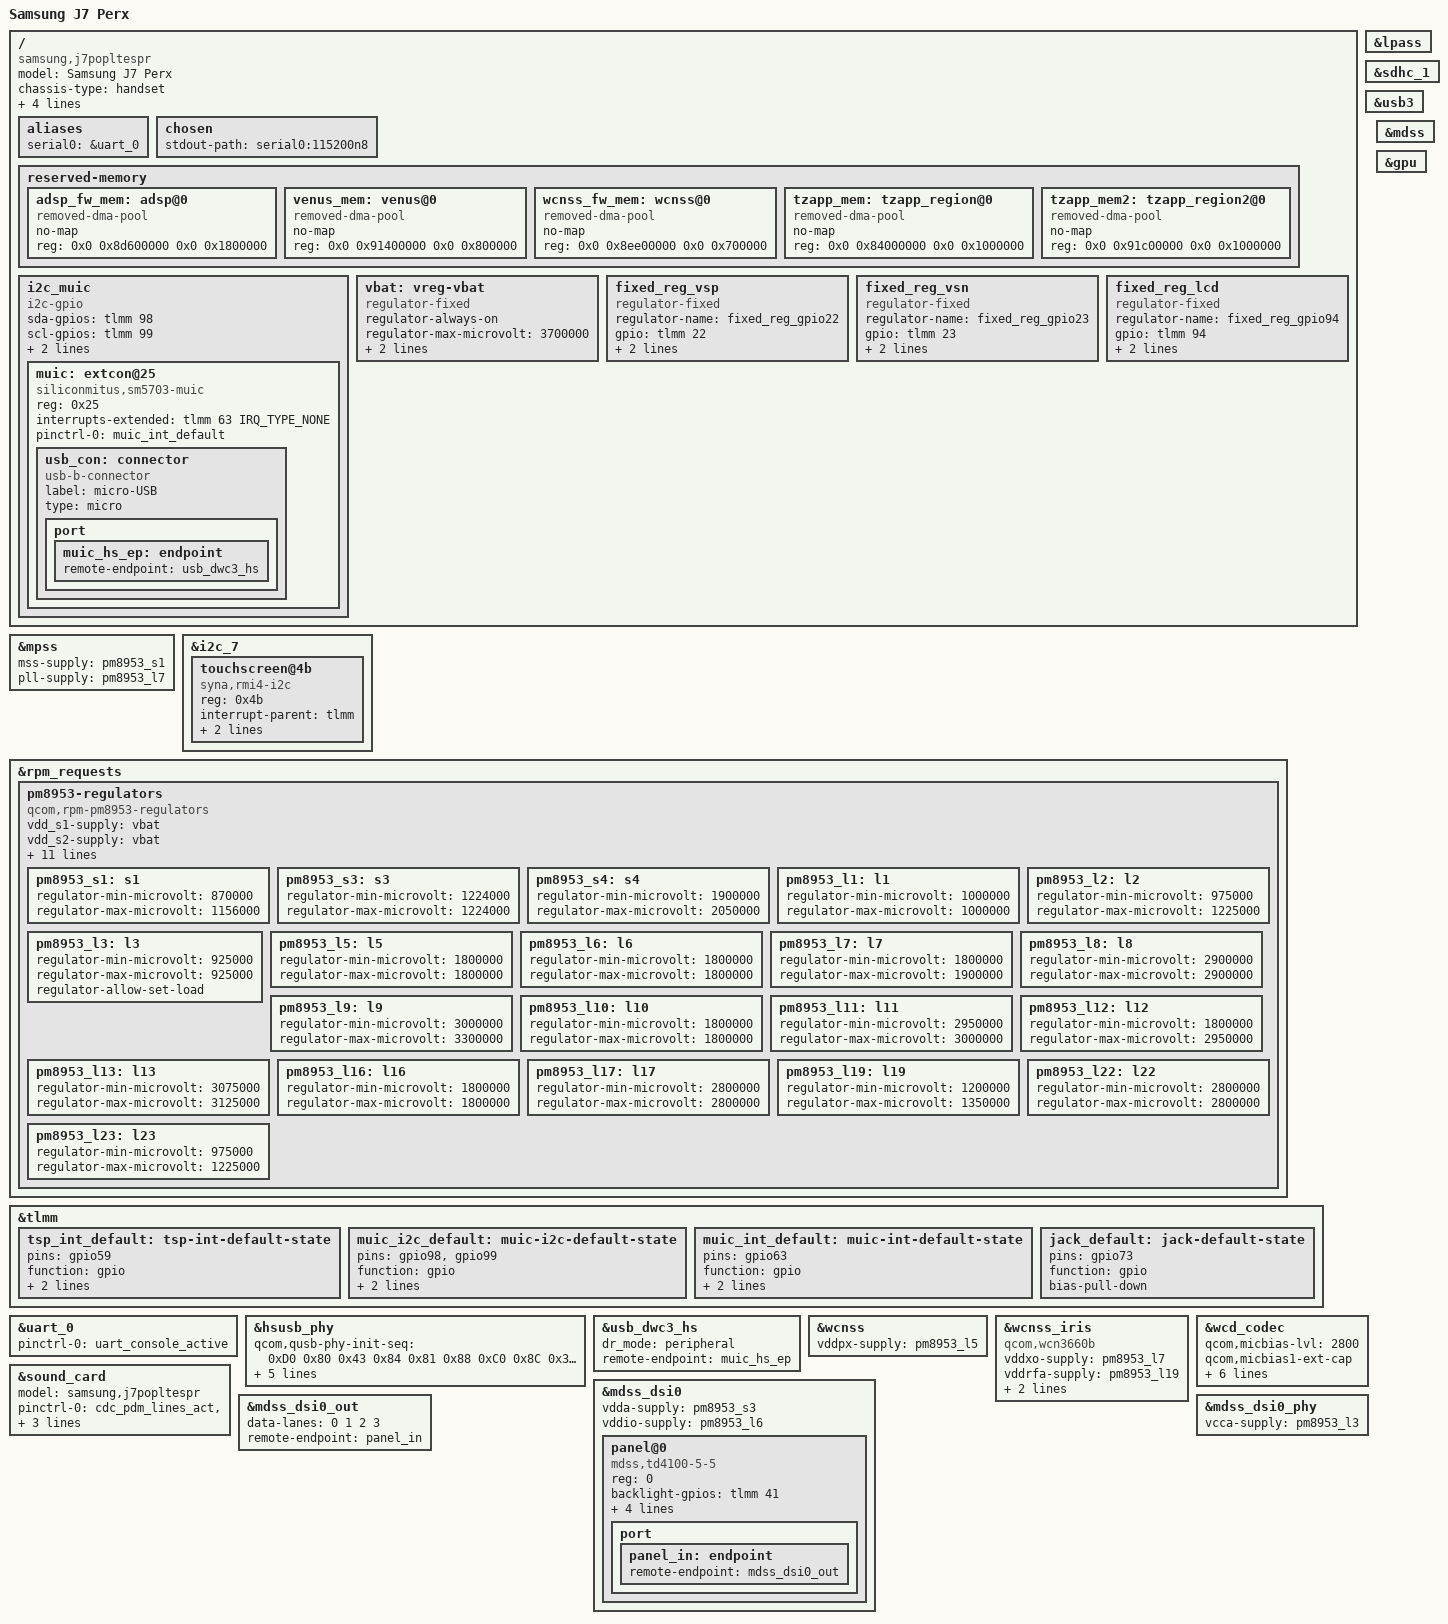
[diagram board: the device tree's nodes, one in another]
// SPDX-License-Identifier: BSD-3-Clause
/*
 * Copyright (c) 2022, Sireesh Kodali
 */
/dts-v1/;

#include "msm8953.dtsi"
#include <dt-bindings/arm/qcom,ids.h>
#include "pm8953.dtsi"
#include "pmi8950.dtsi"

/delete-node/ &cont_splash_mem;
/delete-node/ &qseecom_mem;

/ {
	model = "Samsung J7 Perx";
	compatible = "samsung,j7popltespr", "qcom,msm8953";
	chassis-type = "handset";
	qcom,msm-id = <QCOM_ID_MSM8953 0>;
	qcom,board-id = <QCOM_BOARD_ID_MTP 1>,
			<QCOM_BOARD_ID_MTP 2>,
			<QCOM_BOARD_ID_MTP 3>,
			<QCOM_BOARD_ID_MTP 4>,
			<QCOM_BOARD_ID_MTP 5>;

	aliases {
		serial0 = &uart_0;
	};


	chosen {
		#address-cells = <2>;
		#size-cells = <2>;
		ranges;
		stdout-path = "serial0:115200n8";
		/*
		framebuffer@90001000 {
			compatible = "simple-framebuffer";
			reg = <0 0x90001000 0 (1280 * 720 * 3)>;
			width = <720>;
			height = <1280>;
			stride = <(720 * 3)>;
			format = "r8g8b8";
		};
		*/
		
	};

	reserved-memory {
		/*
		framebuffer_region@90001000 {
			reg = <0x00 0x90001000 0x00 0x300000>;
			no-map;
		};
		*/
		
		/delete-node/ adsp@8d600000;
		adsp_fw_mem: adsp@0 {
			compatible = "removed-dma-pool";
			no-map;
			reg = <0x0 0x8d600000 0x0 0x1800000>;
		};
		
		/delete-node/ venus@91400000;
		venus_mem: venus@0 {
			compatible = "removed-dma-pool";
			no-map;
			reg = <0x0 0x91400000 0x0 0x800000>;
		};
		
		/delete-node/ wcnss@8e700000;
		wcnss_fw_mem: wcnss@0 {
			compatible = "removed-dma-pool";
			no-map;
			reg = <0x0 0x8ee00000 0x0 0x700000>;
		};

		/delete-node/ tzapp_region@0;
		
		tzapp_mem: tzapp_region@0 {
			compatible = "removed-dma-pool";
			no-map;
			reg = <0x0 0x84000000 0x0 0x1000000>;
		};
		/* Later board/BL revisions move tz_appregion?, either way results in a fail to boot */
		tzapp_mem2: tzapp_region2@0 {
			compatible = "removed-dma-pool";
			no-map;
			reg = <0x0 0x91c00000 0x0 0x1000000>;
		};
	};

	i2c_muic {
		compatible = "i2c-gpio";
		sda-gpios = <&tlmm 98 (GPIO_ACTIVE_HIGH|GPIO_OPEN_DRAIN)>;
		scl-gpios = <&tlmm 99 (GPIO_ACTIVE_HIGH|GPIO_OPEN_DRAIN)>;

		pinctrl-names = "default";
		pinctrl-0 = <&muic_i2c_default>;
		i2c-gpio,delay-us = <2>;

		#address-cells = <1>;
		#size-cells = <0>;

		muic: extcon@25 {
			compatible = "siliconmitus,sm5703-muic";
			reg = <0x25>;

			interrupts-extended = <&tlmm 63 IRQ_TYPE_NONE>;

			pinctrl-names = "default";
			pinctrl-0 = <&muic_int_default>;

			usb_con: connector {
				compatible = "usb-b-connector";
				label = "micro-USB";
				type = "micro";

				port {
					muic_hs_ep: endpoint {
						remote-endpoint = <&usb_dwc3_hs>;
					};

				};

			};									
		};
	};

	vbat: vreg-vbat {
		compatible = "regulator-fixed";
		regulator-always-on;
		regulator-max-microvolt = <3700000>;
		regulator-min-microvolt = <3700000>;
		regulator-name = "VBAT";
	};
	
	/* VSP 5.4V */
	fixed_reg_vsp: fixed_reg_vsp {
		 compatible = "regulator-fixed";
		 status = "okay";
		 regulator-name = "fixed_reg_gpio22";
		 gpio = <&tlmm 22 0>; // PANEL_ENP
		 enable-active-high;
		 regulator-boot-on;
	};

	/* VSN -5.4V */
	fixed_reg_vsn: fixed_reg_vsn {
		 compatible = "regulator-fixed";
		 status = "okay";
		 regulator-name = "fixed_reg_gpio23";
		 gpio = <&tlmm 23 0>; // PANEL_ENN
		 enable-active-high;
		 regulator-boot-on;
	};


	fixed_reg_lcd: fixed_reg_lcd {
		 compatible = "regulator-fixed";
		 status = "okay";
		 regulator-name = "fixed_reg_gpio94";
		 gpio = <&tlmm 94 0>;
		 enable-active-high;
		 regulator-boot-on;
	};



};

&mpss {
	mss-supply = <&pm8953_s1>;
	pll-supply = <&pm8953_l7>;

	status = "okay";
};

&i2c_7 {
	status = "okay";

	touchscreen@4b {
		reg = <0x4b>;
		compatible = "syna,rmi4-i2c";

		interrupt-parent = <&tlmm>;
		interrupts = <59 IRQ_TYPE_EDGE_FALLING>;

		pinctrl-names = "default";
		pinctrl-0 = <&tsp_int_default>;
	};
};

&lpass {
	status = "okay";
};

&rpm_requests {
	pm8953-regulators {
		compatible = "qcom,rpm-pm8953-regulators";
		vdd_s1-supply = <&vbat>;
		vdd_s2-supply = <&vbat>;
		vdd_s3-supply = <&vbat>;
		vdd_s4-supply = <&vbat>;
		vdd_s5-supply = <&vbat>;
		vdd_s6-supply = <&vbat>;
		vdd_s7-supply = <&vbat>;
		vdd_l1-supply = <&pm8953_s3>;
		vdd_l2_l3-supply = <&pm8953_s3>;
		vdd_l4_l5_l6_l7_l16_l19-supply = <&pm8953_s4>;
		vdd_l8_l11_l12_l13_l14_l15-supply = <&vbat>;
		vdd_l9_l10_l17_l18_l22-supply = <&vbat>;
		vdd_l23-supply = <&pm8953_s3>;

		pm8953_s1: s1 {
			regulator-min-microvolt = <870000>;
			regulator-max-microvolt = <1156000>;
		};


		pm8953_s3: s3 {
			regulator-min-microvolt = <1224000>;
			regulator-max-microvolt = <1224000>;
		};

		pm8953_s4: s4 {
			regulator-min-microvolt = <1900000>;
			regulator-max-microvolt = <2050000>;
		};

		pm8953_l1: l1 {
			regulator-min-microvolt = <1000000>;
			regulator-max-microvolt = <1000000>;
		};

		pm8953_l2: l2 {
			regulator-min-microvolt = <975000>;
			regulator-max-microvolt = <1225000>;
		};

		pm8953_l3: l3 {
			regulator-min-microvolt = <925000>;
			regulator-max-microvolt = <925000>;
			regulator-allow-set-load;
		};

		pm8953_l5: l5 {
			regulator-min-microvolt = <1800000>;
			regulator-max-microvolt = <1800000>;
		};

		pm8953_l6: l6 {
			regulator-min-microvolt = <1800000>;
			regulator-max-microvolt = <1800000>;
		};

		pm8953_l7: l7 {
			regulator-min-microvolt = <1800000>;
			regulator-max-microvolt = <1900000>;
		};

		pm8953_l8: l8 {
			regulator-min-microvolt = <2900000>;
			regulator-max-microvolt = <2900000>;
		};

		pm8953_l9: l9 {
			regulator-min-microvolt = <3000000>;
			regulator-max-microvolt = <3300000>;
		};

		pm8953_l10: l10 {
			regulator-min-microvolt = <1800000>;
			regulator-max-microvolt = <1800000>;
		};

		pm8953_l11: l11 {
			regulator-min-microvolt = <2950000>;
			regulator-max-microvolt = <3000000>;
		};

		pm8953_l12: l12 {
			regulator-min-microvolt = <1800000>;
			regulator-max-microvolt = <2950000>;
		};

		pm8953_l13: l13 {
			regulator-min-microvolt = <3075000>;
			regulator-max-microvolt = <3125000>;
		};

		pm8953_l16: l16 {
			regulator-min-microvolt = <1800000>;
			regulator-max-microvolt = <1800000>;
		};

		pm8953_l17: l17 {
			regulator-min-microvolt = <2800000>;
			regulator-max-microvolt = <2800000>;
		};

		pm8953_l19: l19 {
			regulator-min-microvolt = <1200000>;
			regulator-max-microvolt = <1350000>;
		};

		pm8953_l22: l22 {
			regulator-min-microvolt = <2800000>;
			regulator-max-microvolt = <2800000>;
		};

		pm8953_l23: l23 {
			regulator-min-microvolt = <975000>;
			regulator-max-microvolt = <1225000>;
		};
	};
};



&tlmm {
	tsp_int_default: tsp-int-default-state {
		pins = "gpio59";
		function = "gpio";
		
		drive-strength = <2>;
		bias-disable;
	};
	muic_i2c_default: muic-i2c-default-state {
		pins = "gpio98", "gpio99";
		function = "gpio";

		drive-strength = <2>;
		bias-disable;
	};

	muic_int_default: muic-int-default-state {
		pins = "gpio63";
		function = "gpio";

		drive-strength = <2>;
		bias-disable;
	};
	jack_default: jack-default-state {
		pins = "gpio73";
		function = "gpio";
		bias-pull-down;
	};
};

&sdhc_1 {
	status = "okay";
};


&uart_0 {
        pinctrl-0 = <&uart_console_active>;
        pinctrl-names = "default";

        status = "okay"; 
};

&usb3 {
	status = "okay";
};

&hsusb_phy {
	qcom,qusb-phy-init-seq = <0xD0 0x80
				0x43 0x84
				0x81 0x88
				0xC0 0x8C
				0x30 0x08
				0x79 0x0C
				0x21 0x10
				0x14 0x9C
				0x9F 0x1C
				0x00 0x18>;
	qcom,qusb-phy-init-seq-host = <0xD0 0x80
				0xA3 0x84
				0x81 0x88
				0xC0 0x8C
				0x30 0x08
				0x79 0x0C
				0x21 0x10
				0x14 0x9C
				0x9F 0x1C
				0x00 0x18>;
	vdd-supply = <&pm8953_l3>;
	vdda-pll-supply = <&pm8953_l7>;
	vdda-phy-dpdm-supply = <&pm8953_l13>;
	status = "okay";
};

&usb_dwc3_hs {
	dr_mode = "peripheral";
	remote-endpoint = <&muic_hs_ep>;
};

&wcnss {
	vddpx-supply = <&pm8953_l5>;
	status = "okay";
};

&wcnss_iris {
	compatible = "qcom,wcn3660b";
	vddxo-supply = <&pm8953_l7>;
	vddrfa-supply = <&pm8953_l19>;
	vddpa-supply = <&pm8953_l9>;
	vdddig-supply = <&pm8953_l5>;
	status = "okay";
};

&wcd_codec {
	qcom,micbias-lvl = <2800>;
	qcom,micbias1-ext-cap;
	qcom,micbias2-ext-cap;
	qcom,mbhc-vthreshold-low = <150 225 450 500 600>;
	qcom,mbhc-vthreshold-high = <150 225 450 500 600>;
	vdd-cdc-io-supply = <&pm8953_l5>;
	vdd-cdc-tx-rx-cx-supply = <&pm8953_s4>;
	vdd-micbias-supply = <&pm8953_l13>;
	status = "okay";
};

&sound_card {
	model = "samsung,j7popltespr";
	status = "okay";
	
	pinctrl-names = "default", "sleep";
	pinctrl-0 = <&cdc_pdm_lines_act &cdc_pdm_lines_2_act &cdc_pdm_comp_lines_act>;
	pinctrl-1 = <&cdc_pdm_lines_sus &cdc_pdm_lines_2_sus &cdc_pdm_comp_lines_act>;
};

&mdss {
	status = "okay";
};
&gpu {
	status = "okay";
};
&mdss_dsi0 {
	vdda-supply = <&pm8953_s3>;
	vddio-supply = <&pm8953_l6>;
	status = "okay";
	/*
	panel@0 {
		compatible = "syna,td4101-panel";
		reg = <0>;
		
		backlight-gpios = <&tlmm 41 GPIO_ACTIVE_HIGH>;
		reset-gpios = <&tlmm 50 GPIO_ACTIVE_HIGH>;
		vio-supply = <&fixed_reg_lcd>;
		vsn-supply = <&fixed_reg_vsn>;
		vsp-supply = <&fixed_reg_vsp>;
		width-mm = <69>;
		height-mm = <122>;
		panel-timing {
			clock-frequency = <112878360>;
			hactive = <720>;
			hsync-len = <4>;
			hfront-porch = <252>;
			hback-porch = <158>;
			
			vactive = <1280>;
			vsync-len = <127>;
			vfront-porch = <127>;
			vback-porch = <125>;
		
		};
		port {
			panel_in: endpoint {
				remote-endpoint = <&mdss_dsi0_out>;
			};
		};
	};
	*/
	panel@0 {
		compatible = "mdss,td4100-5-5";
		reg = <0>;
		backlight-gpios = <&tlmm 41 GPIO_ACTIVE_HIGH>;
		reset-gpios = <&tlmm 50 GPIO_ACTIVE_HIGH>;
		vio-supply = <&fixed_reg_lcd>;
		vsn-supply = <&fixed_reg_vsn>;
		vsp-supply = <&fixed_reg_vsp>;
		port {
			panel_in: endpoint {
				remote-endpoint = <&mdss_dsi0_out>;
			};
		};
	};
};


&mdss_dsi0_out {
	data-lanes = <0 1 2 3>;
	remote-endpoint = <&panel_in>;
};

&mdss_dsi0_phy {
	vcca-supply = <&pm8953_l3>;
	status = "okay";
};
